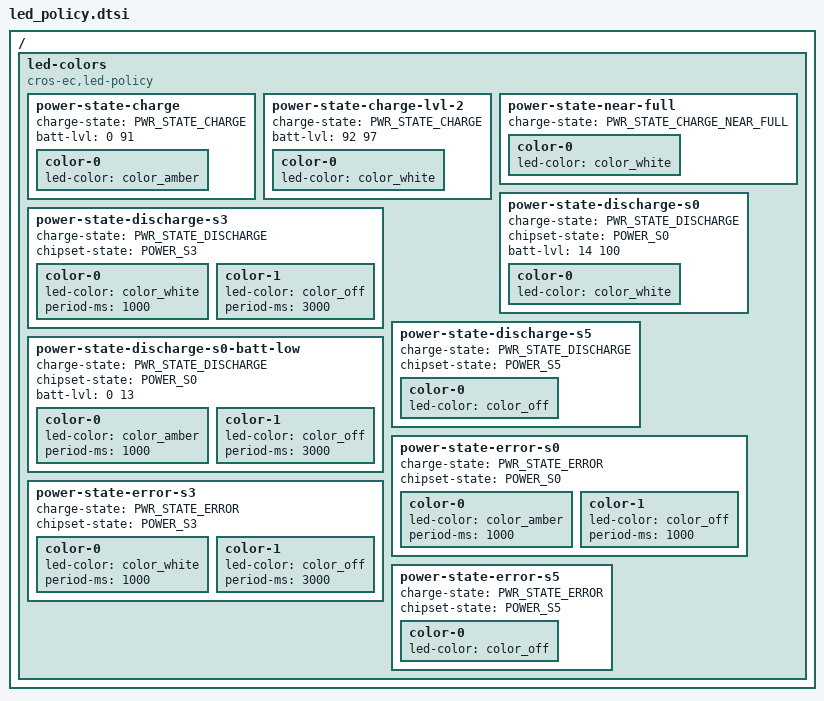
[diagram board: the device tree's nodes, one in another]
/ {
	led-colors {
		compatible = "cros-ec,led-policy";

		power-state-charge {
			charge-state = "PWR_STATE_CHARGE";
			/*
			 * The EC modifies the raw battery level to a 'Display'
			 * level that is then sent to the AP.
			 * The battery percentages that the LED driver uses for
			 * comparison is the raw level, but the Display values
			 * are the ones used to determine the LED thresholds.
			 * The Display values map to raw values as:
			 * Display	Raw
			 * 10%		13%
			 * 11%		14%
			 * 94%		91%
			 * 95%		92%
			 */

			/* Battery display percent range (>= Empty, <= 94%) */
			batt-lvl = <0 91>;

			color-0 {
				led-color = <&color_amber>;
			};
		};

		power-state-charge-lvl-2 {
			charge-state = "PWR_STATE_CHARGE";
			/*
			 * Battery display percent range
			 * (>= 95%, <= Near Full)
			 */
			batt-lvl = <92 97>;

			color-0 {
				led-color = <&color_white>;
			};
		};

		power-state-near-full {
			charge-state = "PWR_STATE_CHARGE_NEAR_FULL";

			color-0 {
				led-color = <&color_white>;
			};
		};

		power-state-discharge-s0 {
			charge-state = "PWR_STATE_DISCHARGE";
			chipset-state = "POWER_S0";
			/* Battery display percent range (>= 11%, <= Full) */
			batt-lvl = <14 100>;

			color-0 {
				led-color = <&color_white>;
			};
		};

		power-state-discharge-s3 {
			charge-state = "PWR_STATE_DISCHARGE";
			chipset-state = "POWER_S3";

			/* White 1 sec, off 3 sec */
			color-0 {
				led-color = <&color_white>;
				period-ms = <1000>;
			};
			color-1 {
				led-color = <&color_off>;
				period-ms = <3000>;
			};
		};

		power-state-discharge-s5 {
			charge-state = "PWR_STATE_DISCHARGE";
			chipset-state = "POWER_S5";

			color-0 {
				led-color = <&color_off>;
			};
		};

		power-state-discharge-s0-batt-low {
			charge-state = "PWR_STATE_DISCHARGE";
			chipset-state = "POWER_S0";
			/* Battery display percent range (>= Empty, <= 10%) */
			batt-lvl = <0 13>;

			/* Amber 1 sec, off 3 sec */
			color-0 {
				led-color = <&color_amber>;
				period-ms = <1000>;
			};
			color-1 {
				led-color = <&color_off>;
				period-ms = <3000>;
			};
		};

		power-state-error-s0 {
			charge-state = "PWR_STATE_ERROR";
			chipset-state = "POWER_S0";
			/* Amber 1 sec, off 1 sec */
			color-0 {
				led-color = <&color_amber>;
				period-ms = <1000>;
			};
			color-1 {
				led-color = <&color_off>;
				period-ms = <1000>;
			};
		};

		power-state-error-s3 {
			charge-state = "PWR_STATE_ERROR";
			chipset-state = "POWER_S3";
			/* White 1 sec, off 3 sec */
			color-0 {
				led-color = <&color_white>;
				period-ms = <1000>;
			};
			color-1 {
				led-color = <&color_off>;
				period-ms = <3000>;
			};
		};

		power-state-error-s5 {
			charge-state = "PWR_STATE_ERROR";
			chipset-state = "POWER_S5";

			color-0 {
				led-color = <&color_off>;
			};
		};
	};
};
